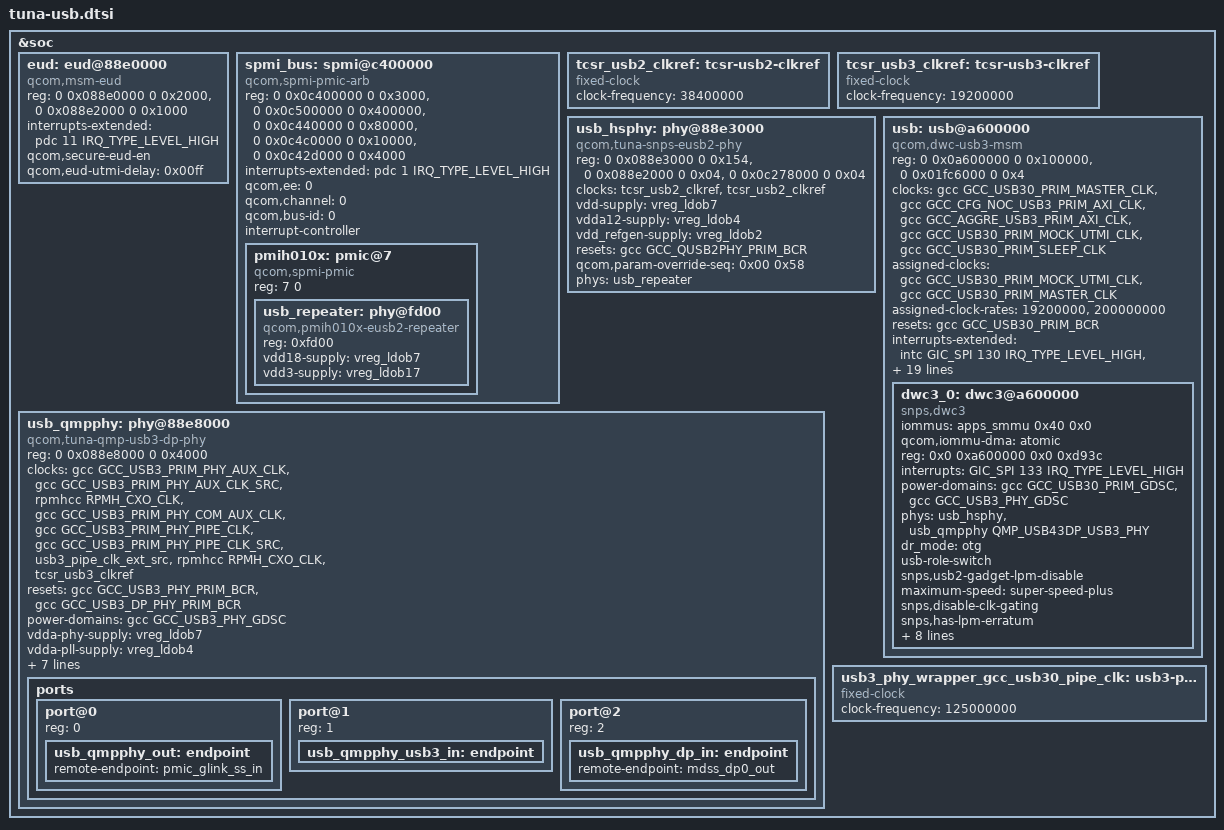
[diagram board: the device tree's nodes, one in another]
// SPDX-License-Identifier: BSD-3-Clause
/* USB peripheral (gadget) path, for early USB CDC ACM diagnostics. */
#include <dt-bindings/phy/phy-qcom-qmp.h>
&soc {
	/* Meizu factory EUD attach/VBUS detector; data role stays peripheral here. */
	eud: eud@88e0000 {
		compatible = "qcom,msm-eud", "qcom,eud";
		reg = <0 0x088e0000 0 0x2000>,
		      <0 0x088e2000 0 0x1000>;
		reg-names = "eud_base", "eud_mode_mgr2";
		interrupts-extended = <&pdc 11 IRQ_TYPE_LEVEL_HIGH>;
		interrupt-names = "eud_irq";
		qcom,secure-eud-en;
		qcom,eud-utmi-delay = /bits/ 16 <0x00ff>;
		status = "okay";
	};

	spmi_bus: spmi@c400000 {
		compatible = "qcom,spmi-pmic-arb";
		reg = <0 0x0c400000 0 0x3000>, <0 0x0c500000 0 0x400000>,
		      <0 0x0c440000 0 0x80000>, <0 0x0c4c0000 0 0x10000>,
		      <0 0x0c42d000 0 0x4000>;
		reg-names = "core", "chnls", "obsrvr", "intr", "cnfg";
		interrupts-extended = <&pdc 1 IRQ_TYPE_LEVEL_HIGH>;
		interrupt-names = "periph_irq";
		qcom,ee = <0>;
		qcom,channel = <0>;
		qcom,bus-id = <0>;
		interrupt-controller;
		#interrupt-cells = <4>;
		#address-cells = <2>;
		#size-cells = <0>;
		pmih010x: pmic@7 {
			compatible = "qcom,spmi-pmic";
			reg = <7 0>;
			#address-cells = <1>;
			#size-cells = <0>;
			usb_repeater: phy@fd00 {
				compatible = "qcom,pmih010x-eusb2-repeater";
				reg = <0xfd00>;
				#phy-cells = <0>;
				vdd18-supply = <&vreg_ldob7>;
				vdd3-supply = <&vreg_ldob17>;
			};
		};
	};

	/* The eUSB2 reference is 38.4 MHz; its rate selects the PHY tuning table. */
	tcsr_usb2_clkref: tcsr-usb2-clkref {
		compatible = "fixed-clock";
		#clock-cells = <0>;
		clock-frequency = <38400000>;
	};

	/*
	 * USB3 reference gate. The real one lives in the TCSR block, which the
	 * non-secure kernel must not touch; ABL has already enabled it. The DWC3
	 * node lists it as "xo", matching the working sm8650 node.
	 */
	tcsr_usb3_clkref: tcsr-usb3-clkref {
		compatible = "fixed-clock";
		#clock-cells = <0>;
		clock-frequency = <19200000>;
	};

	usb_hsphy: phy@88e3000 {
		/* The tuna driver data supplies the QCOM PLL setup and both reference clocks. */
		compatible = "qcom,tuna-snps-eusb2-phy";
		/*
		 * M2582: all three regions, exactly as the factory has them. The
		 * driver only used the first, but the vendor's own init calls
		 * msm_eusb2_phy_power() *before* the register sequence and that
		 * function writes eud_enable_reg -- the second region. Without it
		 * mapped the PHY's APB access window never opens, which matches what
		 * we measure: writing APB_ACCESS_CMD (0x130) reads back 0, i.e. the
		 * write is discarded, while writes to other registers appear to land.
		 */
		reg = <0 0x088e3000 0 0x154>,
		      <0 0x088e2000 0 0x04>,
		      <0 0x0c278000 0 0x04>;
		reg-names = "eusb2_phy_base", "eud_enable_reg", "eud_detect_reg";
		/*
		 * Fixed-rate providers avoid probing protected USB TCSR registers.
		 * The PHY driver enables only the required reference gates.
		 */
		clocks = <&tcsr_usb2_clkref>, <&tcsr_usb2_clkref>;
		clock-names = "ref", "ref_gate";
		/* PMXR2230 L7 supplies the PHY I/O rail at 1.8 V in the factory runtime state. */
		vdd-supply = <&vreg_ldob7>;
		vdda12-supply = <&vreg_ldob4>;
		/*
		 * M2582: the factory node has a third rail here, vdd_refgen, which
		 * feeds the eUSB2 reference generator (PMXR2230 L2B, 0.88 V).
		 * Mainline's driver only knows vdd/vdda12, so this rail was never
		 * enabled and the data path never got its reference.
		 */
		vdd_refgen-supply = <&vreg_ldob2>;
		resets = <&gcc GCC_QUSB2PHY_PRIM_BCR>;
		reset-names = "phy_reset";
		/*
		 * The factory's eUSB2 node carries this and the vendor driver
		 * applies it as (value, offset) pairs after the PHY is up, i.e.
		 * writel(0x00, base + 0x58) -- the eUSB2 HPG v1.0.2 update.
		 * Without it the HS link falls back to full speed right after
		 * CONNECT_DONE and enumeration dies at SET_ADDRESS.
		 */
		qcom,param-override-seq = <0x00 0x58>;

		/* The PMIC repeater completes the high-speed signal path. */
		phys = <&usb_repeater>;
		#phy-cells = <0>;
	};

	/*
	 * USB3/DP QMP combo PHY. Only the USB3 half matters here: the DWC_usb32
	 * core will not complete its soft reset until its pipe clock toggles,
	 * and this PHY's phy_init() is what brings that clock up. Its register
	 * tables are byte-for-byte the SM8750 ones, so the in-tree driver's
	 * sm8750_usb3dpphy_cfg is used as-is and nothing here needs a
	 * qmp-phy-init-seq table.
	 */
	usb_qmpphy: phy@88e8000 {
		compatible = "qcom,tuna-qmp-usb3-dp-phy", "qcom,sm8750-qmp-usb3-dp-phy";
		reg = <0 0x088e8000 0 0x4000>;



		/*
		 * cfg_ahb is the register interface's clock; without it the PHY's register
		 * file cannot latch writes at all -- a write/read-back of 0xa5a5a5a5 across
		 * the window returns the original values bit for bit, which is why the
		 * pre-init and post-init states were identical and the PLL never locked.
		 * GCC_USB3_PRIM_PHY_AUX_CLK_SRC is the live AUX source.
		 */
		/*
		 * The factory enables the reference, register-interface and PIPE mux
		 * clocks as well as the PHY clocks; all must participate in bulk enable.
		 */
		clocks = <&gcc GCC_USB3_PRIM_PHY_AUX_CLK>,
			 <&gcc GCC_USB3_PRIM_PHY_AUX_CLK_SRC>,
			 <&rpmhcc RPMH_CXO_CLK>,
			 <&gcc GCC_USB3_PRIM_PHY_COM_AUX_CLK>,
			 <&gcc GCC_USB3_PRIM_PHY_PIPE_CLK>,
			 <&gcc GCC_USB3_PRIM_PHY_PIPE_CLK_SRC>,
			 <&usb3_pipe_clk_ext_src>,
			 <&rpmhcc RPMH_CXO_CLK>,
			 <&tcsr_usb3_clkref>;
		clock-names = "aux", "cfg_ahb", "ref", "com_aux", "usb3_pipe",
			      "pipe_clk_mux", "pipe_clk_ext_src", "ref_clk_src",
			      "ref_clk";

		/*
		 * The factory global and PHY resets are GCC_USB3_DP_PHY_PRIM_BCR
		 * and GCC_USB3_PHY_PRIM_BCR respectively.
		 */
		resets = <&gcc GCC_USB3_PHY_PRIM_BCR>,
			 <&gcc GCC_USB3_DP_PHY_PRIM_BCR>;
		reset-names = "phy", "common";

		power-domains = <&gcc GCC_USB3_PHY_GDSC>;

		/*
		 * The verified supplies are L7 for PHY I/O and L4 for PLL.
		 * Factory consumer names do not map directly to the generic PHY API.
		 */
		vdda-phy-supply = <&vreg_ldob7>;
		vdda-pll-supply = <&vreg_ldob4>;

		/*
		 * Taken from the factory node. Its driver (phy-msm-ssusb-qmp.ko, in
		 * msm_ssusb_qmp_ldo_enable) calls regulator_set_voltage() and
		 * regulator_set_load() with these; mainline only enables the
		 * regulators and leaves them at whatever the rail defaults to.
		 *   0xd6d80 = 880000 uV, 0xb798 = 47000 uA
		 */
		qcom,vdd-voltage-level = <0 880000 880000>;
		qcom,vdd-max-load-uA = <47000>;
		qcom,core-voltage-level = <0 880000 880000>;
		qcom,core-max-load-uA = <47000>;

		#clock-cells = <1>;
		#phy-cells = <1>;
		status = "okay";


		/*
		 * ADSP GLINK altmode events configure the mux and orientation switch.
		 * Both interfaces must be published for dynamic USB/DP lane routing.
		 */
		mode-switch;
		orientation-switch;
		/* Factory qcom,aux-sel-gpio: follow Type-C orientation, active high. */
		aux-sel-gpios = <&tlmm 149 GPIO_ACTIVE_HIGH>;

		/*
		 * Port 0 reaches the connector HPD bridge, port 1 carries USB3 and
		 * port 2 receives DP. Static data-lanes on the PHY are incompatible
		 * with Type-C mux-controlled routing.
		 */
		ports {
			#address-cells = <1>;
			#size-cells = <0>;

			port@0 {
				reg = <0>;

				usb_qmpphy_out: endpoint {
					remote-endpoint = <&pmic_glink_ss_in>;
				};
			};

			port@1 {
				reg = <1>;

				usb_qmpphy_usb3_in: endpoint {
				};
			};

			port@2 {
				reg = <2>;

				usb_qmpphy_dp_in: endpoint {
					remote-endpoint = <&mdss_dp0_out>;
				};
			};
		};
	};

	/*
	 * The vendor DWC3 glue uses generic PHYs with IPA/GSI offload disabled.
	 * Its 1 MiB core window includes the DBM block at offset 0xf8000.
	 */
	usb: usb@a600000 {
		compatible = "qcom,dwc-usb3-msm";
		reg = <0 0x0a600000 0 0x100000>,
		      <0 0x01fc6000 0 0x4>;
		reg-names = "core_base", "tcsr_dyn_en_dis";

		#address-cells = <2>;
		#size-cells = <2>;
		ranges;

		clocks = <&gcc GCC_USB30_PRIM_MASTER_CLK>,
			 <&gcc GCC_CFG_NOC_USB3_PRIM_AXI_CLK>,
			 <&gcc GCC_AGGRE_USB3_PRIM_AXI_CLK>,
			 <&gcc GCC_USB30_PRIM_MOCK_UTMI_CLK>,
			 <&gcc GCC_USB30_PRIM_SLEEP_CLK>;
		clock-names = "core_clk", "iface_clk", "bus_aggr_clk",
			      "utmi_clk", "sleep_clk";
		assigned-clocks = <&gcc GCC_USB30_PRIM_MOCK_UTMI_CLK>,
				  <&gcc GCC_USB30_PRIM_MASTER_CLK>;
		assigned-clock-rates = <19200000>, <200000000>;

		resets = <&gcc GCC_USB30_PRIM_BCR>;
		reset-names = "core_reset";

		interrupts-extended = <&intc GIC_SPI 130 IRQ_TYPE_LEVEL_HIGH>,
				      <&pdc 14 IRQ_TYPE_EDGE_RISING>,
				      <&pdc 15 IRQ_TYPE_EDGE_RISING>,
				      <&pdc 17 IRQ_TYPE_LEVEL_HIGH>;
		interrupt-names = "pwr_event_irq", "dp_hs_phy_irq",
				  "dm_hs_phy_irq", "ss_phy_irq";

		power-domains = <&gcc GCC_USB30_PRIM_GDSC>;
		required-opps = <&rpmhpd_opp_nom>;

		interconnects = <&aggre1_noc MASTER_USB3_0 QCOM_ICC_TAG_ALWAYS
				 &mc_virt SLAVE_EBI1 QCOM_ICC_TAG_ALWAYS>,
				<&gem_noc MASTER_APPSS_PROC QCOM_ICC_TAG_ALWAYS
				 &config_noc SLAVE_USB3_0 QCOM_ICC_TAG_ALWAYS>;
		interconnect-names = "usb-ddr", "apps-usb";

		qcom,use-pdc-interrupts;
		qcom,use-eusb2-phy;
		usb-role-switch;
		qcom,dis-sending-cm-l1-quirk;
		qcom,core-clk-rate = <200000000>;
		qcom,core-clk-rate-hs = <66666667>;
		qcom,core-clk-rate-disconnected = <133333333>;
		qcom,pm-qos-latency = <2>;

		dma-coherent;

		dwc3_0: dwc3@a600000 {
			/*
			 * The factory node carries iommus = <&apps_smmu 0x40 0x0> and a
			 * memory-region reserving IOVA 0x0..0x90000000. With
			 * CONFIG_ARM_SMMU_DISABLE_BYPASS_BY_DEFAULT and
			 * CONFIG_IOMMU_DEFAULT_DMA_STRICT set, an iommus-less controller has no
			 * usable mapping: the event buffer lands near 0x8090_8000, the controller's
			 * writes to it are dropped and EP0 never sees a real event.
			 */
			iommus = <&apps_smmu 0x40 0x0>;
			qcom,iommu-dma = "atomic";
			compatible = "snps,dwc3";
			reg = <0x0 0xa600000 0x0 0xd93c>;

			interrupts = <GIC_SPI 133 IRQ_TYPE_LEVEL_HIGH>;

			/*
			 * Attach the USB and PHY GDSCs to the core so its runtime PM
			 * activates them through the genpd framework.
			 */
			power-domains = <&gcc GCC_USB30_PRIM_GDSC>,
					<&gcc GCC_USB3_PHY_GDSC>;

			/*
			 * Both PHYs, as the vendor DT has them. The USB3 QMP PHY must be
			 * attached: clk_summary showed gcc_usb3_prim_phy_pipe_clk with
			 * enable_cnt = 0 when only the HS PHY was referenced, and a
			 * DWC_usb32 core will not complete DCTL.CSFTRST until that PIPE
			 * clock is toggling. Nothing else powers the PHY on.
			 */
			/*
			 * The PHY drivers register the generic PHY API, so use phys/phy-names
			 * rather than the vendor legacy usb-phy property.
			 */
			phys = <&usb_hsphy>, <&usb_qmpphy QMP_USB43DP_USB3_PHY>;
			phy-names = "usb2-phy", "usb3-phy";

			dr_mode = "otg";
			usb-role-switch;

			/*
			 * Do not advertise USB2 Link Power Management. The vendor's running kernel
			 * has DCFG 0x00a0082d and DCTL 0x80f00000 against our 0x00e00805 and
			 * 0x8f000000 -- bit 22 (LPM_CAP) and the HIRD_THRES field are set only in
			 * ours, and the two registers agree with each other on both sides.
			 * With LPM_CAP advertised the host may put the link into L1 and it then sits
			 * suspended instead of answering: the device attaches at high speed and then
			 * never accepts an address.
			 */
			snps,usb2-gadget-lpm-disable;
			/*
			 * The factory value, restored. maximum-speed is what allows the core to
			 * attempt SuperSpeed at all; set to high-speed the SS link is never tried
			 * and the device can only ever come up on the eUSB2 high-speed PHY. The
			 * vendor's UDC reports super-speed.
			 */
			maximum-speed = "super-speed-plus";

			snps,disable-clk-gating;
			snps,has-lpm-erratum;
			snps,hird-threshold = /bits/ 8 <0x0>;
			snps,is-utmi-l1-suspend;
			snps,dis-u1-entry-quirk;
			snps,dis-u2-entry-quirk;
			/*
			 * Do not let the core suspend the SuperSpeed PHY. GUSB3PIPECTL0 is
			 * 0x030e1002 while the gadget never attaches and 0x030c1002 once the link
			 * comes up; the only bit that changes is SUSPHY (bit 17), so with it set the
			 * core never sees a connect. dwc3_enable_susphy() only sets it when this
			 * quirk is absent, and the vendor's register reads 0x030c1002 with SUSPHY
			 * clear, so it never leaves the SS PHY suspended either.
			 */
			snps,dis_u2_susphy_quirk;
			snps,dis_u3_susphy_quirk;
			snps,ssp-u3-u0-quirk;
			dma-coherent;
		};
	};
	/* USB3 PIPE clock wrapper source, consumed by the GCC node by name. */
	usb3_phy_wrapper_gcc_usb30_pipe_clk: usb3-phy-wrapper-clk {
		compatible = "fixed-clock";
		#clock-cells = <0>;
		clock-frequency = <125000000>;
	};

};

